AUTOSAR XML (schema 4-2-2)
package /STELLANTIS/EPT/COMSWCs
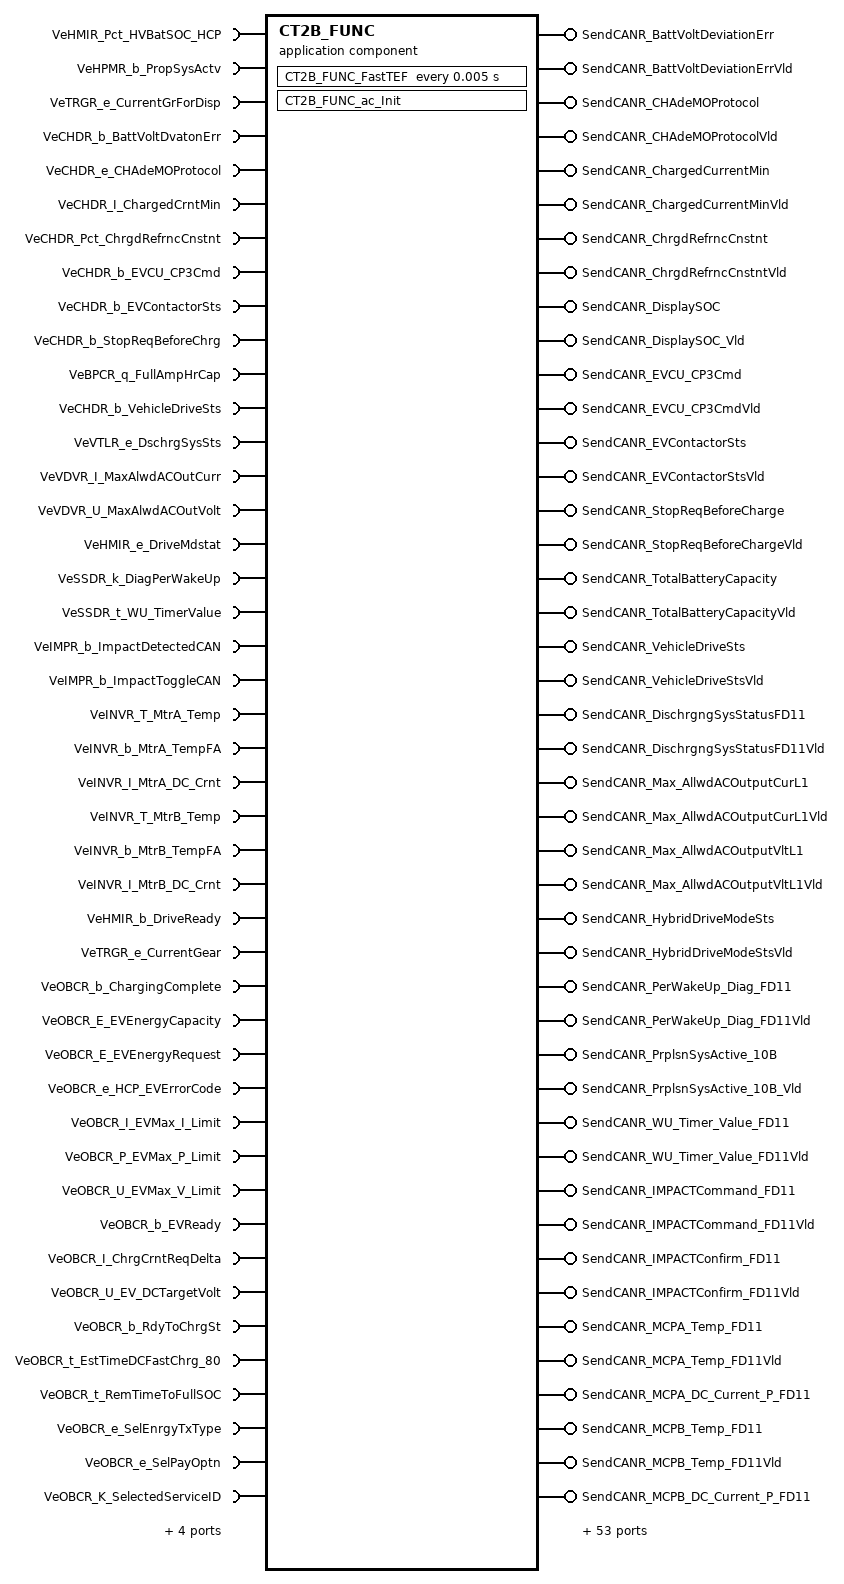
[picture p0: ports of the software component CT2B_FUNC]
  application sw component type CT2B_FUNC
    48 x require port:
      VeHMIR_Pct_HVBatSOC_HCP: nonqueued-receiver-com-spec{data-element=Value, init-value=0}, required-interface=VeHMIR_Pct_HVBatSOC_HCP
      VeHPMR_b_PropSysActv: nonqueued-receiver-com-spec{data-element=Value, init-value=0}, required-interface=VeHPMR_b_PropSysActv
      VeTRGR_e_CurrentGrForDisp: nonqueued-receiver-com-spec{data-element=Value, init-value=0}, required-interface=VeTRGR_e_CurrentGrForDisp
      VeCHDR_b_BattVoltDvatonErr: variation-point={short-label=vpVeCHDR_b_BattVoltDvatonErr, sw-syscond=1}, nonqueued-receiver-com-spec{data-element=Value, init-value=0}, required-interface=VeCHDR_b_BattVoltDvatonErr
      VeCHDR_e_CHAdeMOProtocol: variation-point={short-label=vpVeCHDR_e_CHAdeMOProtocol, sw-syscond=1}, nonqueued-receiver-com-spec{data-element=Value, init-value=CeIDCR_e_CHAdeMO_0_9_n_earlier}, required-interface=VeCHDR_e_CHAdeMOProtocol
      VeCHDR_I_ChargedCrntMin: variation-point={short-label=vpVeCHDR_I_ChargedCrntMin, sw-syscond=1}, nonqueued-receiver-com-spec{data-element=Value, init-value=0}, required-interface=VeCHDR_I_ChargedCrntMin
      VeCHDR_Pct_ChrgdRefrncCnstnt: variation-point={short-label=vpVeCHDR_Pct_ChrgdRefrncCnstnt, sw-syscond=1}, nonqueued-receiver-com-spec{data-element=Value, init-value=0}, required-interface=VeCHDR_Pct_ChrgdRefrncCnstnt
      VeCHDR_b_EVCU_CP3Cmd: variation-point={short-label=vpVeCHDR_b_EVCU_CP3Cmd, sw-syscond=1}, nonqueued-receiver-com-spec{data-element=Value, init-value=0}, required-interface=VeCHDR_b_EVCU_CP3Cmd
      VeCHDR_b_EVContactorSts: variation-point={short-label=vpVeCHDR_b_EVContactorSts, sw-syscond=1}, nonqueued-receiver-com-spec{data-element=Value, init-value=0}, required-interface=VeCHDR_b_EVContactorSts
      VeCHDR_b_StopReqBeforeChrg: variation-point={short-label=vpVeCHDR_b_StopReqBeforeChrg, sw-syscond=1}, nonqueued-receiver-com-spec{data-element=Value, init-value=0}, required-interface=VeCHDR_b_StopReqBeforeChrg
      VeBPCR_q_FullAmpHrCap: variation-point={short-label=vpVeBPCR_q_FullAmpHrCap, sw-syscond=1}, nonqueued-receiver-com-spec{data-element=Value, init-value=0}, required-interface=VeBPCR_q_FullAmpHrCap
      VeCHDR_b_VehicleDriveSts: variation-point={short-label=vpVeCHDR_b_VehicleDriveSts, sw-syscond=1}, nonqueued-receiver-com-spec{data-element=Value, init-value=0}, required-interface=VeCHDR_b_VehicleDriveSts
      VeVTLR_e_DschrgSysSts: nonqueued-receiver-com-spec{data-element=Value, init-value=CeVTLR_e_DschrgInactv}, required-interface=VeVTLR_e_DschrgSysSts
      VeVDVR_I_MaxAlwdACOutCurr: variation-point={short-label=vpVeVDVR_I_MaxAlwdACOutCurr, sw-syscond=1}, nonqueued-receiver-com-spec{data-element=Value, init-value=0}, required-interface=VeVDVR_I_MaxAlwdACOutCurr
      VeVDVR_U_MaxAlwdACOutVolt: variation-point={short-label=vpVeVDVR_U_MaxAlwdACOutVolt, sw-syscond=1}, nonqueued-receiver-com-spec{data-element=Value, init-value=0}, required-interface=VeVDVR_U_MaxAlwdACOutVolt
      VeHMIR_e_DriveMdstat: nonqueued-receiver-com-spec{data-element=Value, init-value=0}, required-interface=VeHMIR_e_DriveMdstat
      VeSSDR_k_DiagPerWakeUp: nonqueued-receiver-com-spec{data-element=Value, init-value=0}, required-interface=VeSSDR_k_DiagPerWakeUp
      VeSSDR_t_WU_TimerValue: nonqueued-receiver-com-spec{data-element=Value, init-value=0}, required-interface=VeSSDR_t_WU_TimerValue
      VeIMPR_b_ImpactDetectedCAN: nonqueued-receiver-com-spec{data-element=Value, init-value=0}, required-interface=VeIMPR_b_ImpactDetectedCAN
      VeIMPR_b_ImpactToggleCAN: nonqueued-receiver-com-spec{data-element=Value, init-value=0}, required-interface=VeIMPR_b_ImpactToggleCAN
      VeINVR_T_MtrA_Temp: variation-point={short-label=vpVeINVR_T_MtrA_Temp, sw-syscond=1}, nonqueued-receiver-com-spec{data-element=Value, init-value=0}, required-interface=VeINVR_T_MtrA_Temp
      VeINVR_b_MtrA_TempFA: variation-point={short-label=vpVeINVR_b_MtrA_TempFA, sw-syscond=1}, nonqueued-receiver-com-spec{data-element=Value, init-value=0}, required-interface=VeINVR_b_MtrA_TempFA
      VeINVR_I_MtrA_DC_Crnt: variation-point={short-label=vpVeINVR_I_MtrA_DC_Crnt, sw-syscond=1}, nonqueued-receiver-com-spec{data-element=Value, init-value=0}, required-interface=VeINVR_I_MtrA_DC_Crnt
      VeINVR_T_MtrB_Temp: nonqueued-receiver-com-spec{data-element=Value, init-value=0}, required-interface=VeINVR_T_MtrB_Temp
      VeINVR_b_MtrB_TempFA: nonqueued-receiver-com-spec{data-element=Value, init-value=0}, required-interface=VeINVR_b_MtrB_TempFA
      VeINVR_I_MtrB_DC_Crnt: nonqueued-receiver-com-spec{data-element=Value, init-value=0}, required-interface=VeINVR_I_MtrB_DC_Crnt
      VeHMIR_b_DriveReady: nonqueued-receiver-com-spec{data-element=Value, init-value=0}, required-interface=VeHMIR_b_DriveReady
      VeTRGR_e_CurrentGear: nonqueued-receiver-com-spec{data-element=Value, init-value=0}, required-interface=VeTRGR_e_CurrentGear
      VeOBCR_b_ChargingComplete: nonqueued-receiver-com-spec{data-element=Value, init-value=0}, required-interface=VeOBCR_b_ChargingComplete
      VeOBCR_E_EVEnergyCapacity: nonqueued-receiver-com-spec{data-element=Value, init-value=0}, required-interface=VeOBCR_E_EVEnergyCapacity
      VeOBCR_E_EVEnergyRequest: nonqueued-receiver-com-spec{data-element=Value, init-value=0}, required-interface=VeOBCR_E_EVEnergyRequest
      VeOBCR_e_HCP_EVErrorCode: nonqueued-receiver-com-spec{data-element=Value, init-value=0}, required-interface=VeOBCR_e_HCP_EVErrorCode
      VeOBCR_I_EVMax_I_Limit: nonqueued-receiver-com-spec{data-element=Value, init-value=0}, required-interface=VeOBCR_I_EVMax_I_Limit
      VeOBCR_P_EVMax_P_Limit: nonqueued-receiver-com-spec{data-element=Value, init-value=0}, required-interface=VeOBCR_P_EVMax_P_Limit
      VeOBCR_U_EVMax_V_Limit: nonqueued-receiver-com-spec{data-element=Value, init-value=0}, required-interface=VeOBCR_U_EVMax_V_Limit
      VeOBCR_b_EVReady: nonqueued-receiver-com-spec{data-element=Value, init-value=0}, required-interface=VeOBCR_b_EVReady
      VeOBCR_I_ChrgCrntReqDelta: nonqueued-receiver-com-spec{data-element=Value, init-value=0}, required-interface=VeOBCR_I_ChrgCrntReqDelta
      VeOBCR_U_EV_DCTargetVolt: nonqueued-receiver-com-spec{data-element=Value, init-value=0}, required-interface=VeOBCR_U_EV_DCTargetVolt
      VeOBCR_b_RdyToChrgSt: nonqueued-receiver-com-spec{data-element=Value, init-value=0}, required-interface=VeOBCR_b_RdyToChrgSt
      VeOBCR_t_EstTimeDCFastChrg_80: nonqueued-receiver-com-spec{data-element=Value, init-value=0}, required-interface=VeOBCR_t_EstTimeDCFastChrg_80
      VeOBCR_t_RemTimeToFullSOC: nonqueued-receiver-com-spec{data-element=Value, init-value=0}, required-interface=VeOBCR_t_RemTimeToFullSOC
      VeOBCR_e_SelEnrgyTxType: nonqueued-receiver-com-spec{data-element=Value, init-value=0}, required-interface=VeOBCR_e_SelEnrgyTxType
      VeOBCR_e_SelPayOptn: nonqueued-receiver-com-spec{data-element=Value, init-value=CeOBCR_e_NoPaymentSel}, required-interface=VeOBCR_e_SelPayOptn
      VeOBCR_K_SelectedServiceID: nonqueued-receiver-com-spec{data-element=Value, init-value=0}, required-interface=VeOBCR_K_SelectedServiceID
      VeOBCR_e_Service_Category: nonqueued-receiver-com-spec{data-element=Value, init-value=0}, required-interface=VeOBCR_e_Service_Category
      VeOBCR_d_ServiceScope: variation-point={short-label=vpVeOBCR_d_ServiceScope, sw-syscond=1}, nonqueued-receiver-com-spec{data-element=Value, init-value=0}, required-interface=VeOBCR_d_ServiceScope
      VeVTHR_b_V2H_SelEnergyTransType: variation-point={short-label=vpVeVTHR_b_V2H_SelEnergyTransType, sw-syscond=1}, nonqueued-receiver-com-spec{data-element=Value, init-value=0}, required-interface=VeVTHR_b_V2H_SelEnergyTransType
      VeVTHR_Pct_V2H_BattBulkSOC: variation-point={short-label=vpVeVTHR_Pct_V2H_BattBulkSOC, sw-syscond=1}, nonqueued-receiver-com-spec{data-element=Value, init-value=0}, required-interface=VeVTHR_Pct_V2H_BattBulkSOC
    97 x provide port:
      SendCANR_BattVoltDeviationErr: variation-point={short-label=vpSendCANR_BattVoltDeviationErr, sw-syscond=1}, nonqueued-sender-com-spec{data-element=SendCANR_BattVoltDeviationErr, init-value=0}, provided-interface=SendCANR_BattVoltDeviationErr
      SendCANR_BattVoltDeviationErrVld: variation-point={short-label=vpSendCANR_BattVoltDeviationErrVld, sw-syscond=1}, nonqueued-sender-com-spec{data-element=SendCANR_BattVoltDeviationErrVld, init-value=0}, provided-interface=SendCANR_BattVoltDeviationErrVld
      SendCANR_CHAdeMOProtocol: variation-point={short-label=vpSendCANR_CHAdeMOProtocol, sw-syscond=1}, nonqueued-sender-com-spec{data-element=SendCANR_CHAdeMOProtocol, init-value=0}, provided-interface=SendCANR_CHAdeMOProtocol
      SendCANR_CHAdeMOProtocolVld: variation-point={short-label=vpSendCANR_CHAdeMOProtocolVld, sw-syscond=1}, nonqueued-sender-com-spec{data-element=SendCANR_CHAdeMOProtocolVld, init-value=0}, provided-interface=SendCANR_CHAdeMOProtocolVld
      SendCANR_ChargedCurrentMin: variation-point={short-label=vpSendCANR_ChargedCurrentMin, sw-syscond=1}, nonqueued-sender-com-spec{data-element=SendCANR_ChargedCurrentMin, init-value=0}, provided-interface=SendCANR_ChargedCurrentMin
      SendCANR_ChargedCurrentMinVld: variation-point={short-label=vpSendCANR_ChargedCurrentMinVld, sw-syscond=1}, nonqueued-sender-com-spec{data-element=SendCANR_ChargedCurrentMinVld, init-value=0}, provided-interface=SendCANR_ChargedCurrentMinVld
      SendCANR_ChrgdRefrncCnstnt: variation-point={short-label=vpSendCANR_ChrgdRefrncCnstnt, sw-syscond=1}, nonqueued-sender-com-spec{data-element=SendCANR_ChrgdRefrncCnstnt, init-value=0}, provided-interface=SendCANR_ChrgdRefrncCnstnt
      SendCANR_ChrgdRefrncCnstntVld: variation-point={short-label=vpSendCANR_ChrgdRefrncCnstntVld, sw-syscond=1}, nonqueued-sender-com-spec{data-element=SendCANR_ChrgdRefrncCnstntVld, init-value=0}, provided-interface=SendCANR_ChrgdRefrncCnstntVld
      SendCANR_DisplaySOC: variation-point={short-label=vpSendCANR_DisplaySOC, sw-syscond=1}, nonqueued-sender-com-spec{data-element=SendCANR_DisplaySOC, init-value=0}, provided-interface=SendCANR_DisplaySOC
      SendCANR_DisplaySOC_Vld: variation-point={short-label=vpSendCANR_DisplaySOC_Vld, sw-syscond=1}, nonqueued-sender-com-spec{data-element=SendCANR_DisplaySOC_Vld, init-value=0}, provided-interface=SendCANR_DisplaySOC_Vld
      SendCANR_EVCU_CP3Cmd: variation-point={short-label=vpSendCANR_EVCU_CP3Cmd, sw-syscond=1}, nonqueued-sender-com-spec{data-element=SendCANR_EVCU_CP3Cmd, init-value=0}, provided-interface=SendCANR_EVCU_CP3Cmd
      SendCANR_EVCU_CP3CmdVld: variation-point={short-label=vpSendCANR_EVCU_CP3CmdVld, sw-syscond=1}, nonqueued-sender-com-spec{data-element=SendCANR_EVCU_CP3CmdVld, init-value=0}, provided-interface=SendCANR_EVCU_CP3CmdVld
      SendCANR_EVContactorSts: variation-point={short-label=vpSendCANR_EVContactorSts, sw-syscond=1}, nonqueued-sender-com-spec{data-element=SendCANR_EVContactorSts, init-value=0}, provided-interface=SendCANR_EVContactorSts
      SendCANR_EVContactorStsVld: variation-point={short-label=vpSendCANR_EVContactorStsVld, sw-syscond=1}, nonqueued-sender-com-spec{data-element=SendCANR_EVContactorStsVld, init-value=0}, provided-interface=SendCANR_EVContactorStsVld
      SendCANR_StopReqBeforeCharge: variation-point={short-label=vpSendCANR_StopReqBeforeCharge, sw-syscond=1}, nonqueued-sender-com-spec{data-element=SendCANR_StopReqBeforeCharge, init-value=0}, provided-interface=SendCANR_StopReqBeforeCharge
      SendCANR_StopReqBeforeChargeVld: variation-point={short-label=vpSendCANR_StopReqBeforeChargeVld, sw-syscond=1}, nonqueued-sender-com-spec{data-element=SendCANR_StopReqBeforeChargeVld, init-value=0}, provided-interface=SendCANR_StopReqBeforeChargeVld
      SendCANR_TotalBatteryCapacity: variation-point={short-label=vpSendCANR_TotalBatteryCapacity, sw-syscond=1}, nonqueued-sender-com-spec{data-element=SendCANR_TotalBatteryCapacity, init-value=0}, provided-interface=SendCANR_TotalBatteryCapacity
      SendCANR_TotalBatteryCapacityVld: variation-point={short-label=vpSendCANR_TotalBatteryCapacityVld, sw-syscond=1}, nonqueued-sender-com-spec{data-element=SendCANR_TotalBatteryCapacityVld, init-value=0}, provided-interface=SendCANR_TotalBatteryCapacityVld
      SendCANR_VehicleDriveSts: variation-point={short-label=vpSendCANR_VehicleDriveSts, sw-syscond=1}, nonqueued-sender-com-spec{data-element=SendCANR_VehicleDriveSts, init-value=0}, provided-interface=SendCANR_VehicleDriveSts
      SendCANR_VehicleDriveStsVld: variation-point={short-label=vpSendCANR_VehicleDriveStsVld, sw-syscond=1}, nonqueued-sender-com-spec{data-element=SendCANR_VehicleDriveStsVld, init-value=0}, provided-interface=SendCANR_VehicleDriveStsVld
      SendCANR_DischrgngSysStatusFD11: nonqueued-sender-com-spec{data-element=SendCANR_DischrgngSysStatusFD11, init-value=0}, provided-interface=SendCANR_DischrgngSysStatusFD11
      SendCANR_DischrgngSysStatusFD11Vld: nonqueued-sender-com-spec{data-element=SendCANR_DischrgngSysStatusFD11Vld, init-value=0}, provided-interface=SendCANR_DischrgngSysStatusFD11Vld
      SendCANR_Max_AllwdACOutputCurL1: variation-point={short-label=vpSendCANR_Max_AllwdACOutputCurL1, sw-syscond=1}, nonqueued-sender-com-spec{data-element=SendCANR_Max_AllwdACOutputCurL1, init-value=0}, provided-interface=SendCANR_Max_AllwdACOutputCurL1
      SendCANR_Max_AllwdACOutputCurL1Vld: variation-point={short-label=vpSendCANR_Max_AllwdACOutputCurL1Vld, sw-syscond=1}, nonqueued-sender-com-spec{data-element=SendCANR_Max_AllwdACOutputCurL1Vld, init-value=0}, provided-interface=SendCANR_Max_AllwdACOutputCurL1Vld
      SendCANR_Max_AllwdACOutputVltL1: variation-point={short-label=vpSendCANR_Max_AllwdACOutputVltL1, sw-syscond=1}, nonqueued-sender-com-spec{data-element=SendCANR_Max_AllwdACOutputVltL1, init-value=0}, provided-interface=SendCANR_Max_AllwdACOutputVltL1
      SendCANR_Max_AllwdACOutputVltL1Vld: variation-point={short-label=vpSendCANR_Max_AllwdACOutputVltL1Vld, sw-syscond=1}, nonqueued-sender-com-spec{data-element=SendCANR_Max_AllwdACOutputVltL1Vld, init-value=0}, provided-interface=SendCANR_Max_AllwdACOutputVltL1Vld
      SendCANR_HybridDriveModeSts: nonqueued-sender-com-spec{data-element=SendCANR_HybridDriveModeSts, init-value=0}, provided-interface=SendCANR_HybridDriveModeSts
      SendCANR_HybridDriveModeStsVld: nonqueued-sender-com-spec{data-element=SendCANR_HybridDriveModeStsVld, init-value=0}, provided-interface=SendCANR_HybridDriveModeStsVld
      SendCANR_PerWakeUp_Diag_FD11: nonqueued-sender-com-spec{data-element=SendCANR_PerWakeUp_Diag_FD11, init-value=0}, provided-interface=SendCANR_PerWakeUp_Diag_FD11
      SendCANR_PerWakeUp_Diag_FD11Vld: nonqueued-sender-com-spec{data-element=SendCANR_PerWakeUp_Diag_FD11Vld, init-value=0}, provided-interface=SendCANR_PerWakeUp_Diag_FD11Vld
      SendCANR_PrplsnSysActive_10B: nonqueued-sender-com-spec{data-element=SendCANR_PrplsnSysActive_10B, init-value=0}, provided-interface=SendCANR_PrplsnSysActive_10B
      SendCANR_PrplsnSysActive_10B_Vld: nonqueued-sender-com-spec{data-element=SendCANR_PrplsnSysActive_10B_Vld, init-value=0}, provided-interface=SendCANR_PrplsnSysActive_10B_Vld
      SendCANR_WU_Timer_Value_FD11: nonqueued-sender-com-spec{data-element=SendCANR_WU_Timer_Value_FD11, init-value=0}, provided-interface=SendCANR_WU_Timer_Value_FD11
      SendCANR_WU_Timer_Value_FD11Vld: nonqueued-sender-com-spec{data-element=SendCANR_WU_Timer_Value_FD11Vld, init-value=0}, provided-interface=SendCANR_WU_Timer_Value_FD11Vld
      SendCANR_IMPACTCommand_FD11: nonqueued-sender-com-spec{data-element=SendCANR_IMPACTCommand_FD11, init-value=0}, provided-interface=SendCANR_IMPACTCommand_FD11
      SendCANR_IMPACTCommand_FD11Vld: nonqueued-sender-com-spec{data-element=SendCANR_IMPACTCommand_FD11Vld, init-value=0}, provided-interface=SendCANR_IMPACTCommand_FD11Vld
      SendCANR_IMPACTConfirm_FD11: nonqueued-sender-com-spec{data-element=SendCANR_IMPACTConfirm_FD11, init-value=0}, provided-interface=SendCANR_IMPACTConfirm_FD11
      SendCANR_IMPACTConfirm_FD11Vld: nonqueued-sender-com-spec{data-element=SendCANR_IMPACTConfirm_FD11Vld, init-value=0}, provided-interface=SendCANR_IMPACTConfirm_FD11Vld
      SendCANR_MCPA_Temp_FD11: variation-point={short-label=vpSendCANR_MCPA_Temp_FD11, sw-syscond=1}, nonqueued-sender-com-spec{data-element=SendCANR_MCPA_Temp_FD11, init-value=0}, provided-interface=SendCANR_MCPA_Temp_FD11
      SendCANR_MCPA_Temp_FD11Vld: variation-point={short-label=vpSendCANR_MCPA_Temp_FD11Vld, sw-syscond=1}, nonqueued-sender-com-spec{data-element=SendCANR_MCPA_Temp_FD11Vld, init-value=0}, provided-interface=SendCANR_MCPA_Temp_FD11Vld
      SendCANR_MCPA_DC_Current_P_FD11: variation-point={short-label=vpSendCANR_MCPA_DC_Current_P_FD11, sw-syscond=1}, nonqueued-sender-com-spec{data-element=SendCANR_MCPA_DC_Current_P_FD11, init-value=0}, provided-interface=SendCANR_MCPA_DC_Current_P_FD11
      SendCANR_MCPB_Temp_FD11: nonqueued-sender-com-spec{data-element=SendCANR_MCPB_Temp_FD11, init-value=0}, provided-interface=SendCANR_MCPB_Temp_FD11
      SendCANR_MCPB_Temp_FD11Vld: nonqueued-sender-com-spec{data-element=SendCANR_MCPB_Temp_FD11Vld, init-value=0}, provided-interface=SendCANR_MCPB_Temp_FD11Vld
      SendCANR_MCPB_DC_Current_P_FD11: nonqueued-sender-com-spec{data-element=SendCANR_MCPB_DC_Current_P_FD11, init-value=0}, provided-interface=SendCANR_MCPB_DC_Current_P_FD11
      SendCANR_MCPB_DC_Current_P_FD11Vld: nonqueued-sender-com-spec{data-element=SendCANR_MCPB_DC_Current_P_FD11Vld, init-value=0}, provided-interface=SendCANR_MCPB_DC_Current_P_FD11Vld
      SendCANR_DriveReady_PT_FD11: nonqueued-sender-com-spec{data-element=SendCANR_DriveReady_PT_FD11, init-value=0}, provided-interface=SendCANR_DriveReady_PT_FD11
      SendCANR_DriveReady_PT_FD11Vld: nonqueued-sender-com-spec{data-element=SendCANR_DriveReady_PT_FD11Vld, init-value=0}, provided-interface=SendCANR_DriveReady_PT_FD11Vld
      SendCANR_GearEngdForDispPTFD11: nonqueued-sender-com-spec{data-element=SendCANR_GearEngdForDispPTFD11, init-value=0}, provided-interface=SendCANR_GearEngdForDispPTFD11
      SendCANR_GearEngdForDispPTFD11Vld: nonqueued-sender-com-spec{data-element=SendCANR_GearEngdForDispPTFD11Vld, init-value=0}, provided-interface=SendCANR_GearEngdForDispPTFD11Vld
      SendCANR_GearEngaged_PT_FD11: nonqueued-sender-com-spec{data-element=SendCANR_GearEngaged_PT_FD11, init-value=0}, provided-interface=SendCANR_GearEngaged_PT_FD11
      SendCANR_GearEngaged_PT_FD11Vld: nonqueued-sender-com-spec{data-element=SendCANR_GearEngaged_PT_FD11Vld, init-value=0}, provided-interface=SendCANR_GearEngaged_PT_FD11Vld
      SendCANR_PtrainPrplsnActvPTFD11: nonqueued-sender-com-spec{data-element=SendCANR_PtrainPrplsnActvPTFD11, init-value=0}, provided-interface=SendCANR_PtrainPrplsnActvPTFD11
      SendCANR_PtrainPrplsnActvPTFD11Vld: nonqueued-sender-com-spec{data-element=SendCANR_PtrainPrplsnActvPTFD11Vld, init-value=0}, provided-interface=SendCANR_PtrainPrplsnActvPTFD11Vld
      SendCANR_GearEngagedForDisplay: nonqueued-sender-com-spec{data-element=SendCANR_GearEngagedForDisplay, init-value=0}, provided-interface=SendCANR_GearEngagedForDisplay
      SendCANR_GearEngagedForDisplayVld: nonqueued-sender-com-spec{data-element=SendCANR_GearEngagedForDisplayVld, init-value=0}, provided-interface=SendCANR_GearEngagedForDisplayVld
      SendCANR_HVCMS_ChrgnCmpl_FD11: nonqueued-sender-com-spec{data-element=SendCANR_HVCMS_ChrgnCmpl_FD11, init-value=0}, provided-interface=SendCANR_HVCMS_ChrgnCmpl_FD11
      SendCANR_HVCMS_ChrgnCmpl_FD11Vld: nonqueued-sender-com-spec{data-element=SendCANR_HVCMS_ChrgnCmpl_FD11Vld, init-value=0}, provided-interface=SendCANR_HVCMS_ChrgnCmpl_FD11Vld
      SendCANR_HVCMS_EVEgyCap_FD11: nonqueued-sender-com-spec{data-element=SendCANR_HVCMS_EVEgyCap_FD11, init-value=0}, provided-interface=SendCANR_HVCMS_EVEgyCap_FD11
      SendCANR_HVCMS_EVEgyCap_FD11Vld: nonqueued-sender-com-spec{data-element=SendCANR_HVCMS_EVEgyCap_FD11Vld, init-value=0}, provided-interface=SendCANR_HVCMS_EVEgyCap_FD11Vld
      SendCANR_HVCMS_EVEgyReq_FD11: nonqueued-sender-com-spec{data-element=SendCANR_HVCMS_EVEgyReq_FD11, init-value=0}, provided-interface=SendCANR_HVCMS_EVEgyReq_FD11
      SendCANR_HVCMS_EVEgyReq_FD11Vld: nonqueued-sender-com-spec{data-element=SendCANR_HVCMS_EVEgyReq_FD11Vld, init-value=0}, provided-interface=SendCANR_HVCMS_EVEgyReq_FD11Vld
      SendCANR_HVCMS_EVErrorCode_FD11: nonqueued-sender-com-spec{data-element=SendCANR_HVCMS_EVErrorCode_FD11, init-value=0}, provided-interface=SendCANR_HVCMS_EVErrorCode_FD11
      SendCANR_HVCMS_EVErrorCode_FD11Vld: nonqueued-sender-com-spec{data-element=SendCANR_HVCMS_EVErrorCode_FD11Vld, init-value=0}, provided-interface=SendCANR_HVCMS_EVErrorCode_FD11Vld
      SendCANR_HVCMS_EVMaxILimit_FD11: nonqueued-sender-com-spec{data-element=SendCANR_HVCMS_EVMaxILimit_FD11, init-value=0}, provided-interface=SendCANR_HVCMS_EVMaxILimit_FD11
      SendCANR_HVCMS_EVMaxILimit_FD11Vld: nonqueued-sender-com-spec{data-element=SendCANR_HVCMS_EVMaxILimit_FD11Vld, init-value=0}, provided-interface=SendCANR_HVCMS_EVMaxILimit_FD11Vld
      SendCANR_HVCMS_EVMaxPLimit_FD11: nonqueued-sender-com-spec{data-element=SendCANR_HVCMS_EVMaxPLimit_FD11, init-value=0}, provided-interface=SendCANR_HVCMS_EVMaxPLimit_FD11
      SendCANR_HVCMS_EVMaxPLimit_FD11Vld: nonqueued-sender-com-spec{data-element=SendCANR_HVCMS_EVMaxPLimit_FD11Vld, init-value=0}, provided-interface=SendCANR_HVCMS_EVMaxPLimit_FD11Vld
      SendCANR_HVCMSEVMaxVLimit_FD11: nonqueued-sender-com-spec{data-element=SendCANR_HVCMSEVMaxVLimit_FD11, init-value=0}, provided-interface=SendCANR_HVCMSEVMaxVLimit_FD11
      SendCANR_HVCMSEVMaxVLimit_FD11Vld: nonqueued-sender-com-spec{data-element=SendCANR_HVCMSEVMaxVLimit_FD11Vld, init-value=0}, provided-interface=SendCANR_HVCMSEVMaxVLimit_FD11Vld
      SendCANR_HVCMS_EVRESS_SOC_FD11: nonqueued-sender-com-spec{data-element=SendCANR_HVCMS_EVRESS_SOC_FD11, init-value=0}, provided-interface=SendCANR_HVCMS_EVRESS_SOC_FD11
      SendCANR_HVCMS_EVRESS_SOC_FD11Vld: nonqueued-sender-com-spec{data-element=SendCANR_HVCMS_EVRESS_SOC_FD11Vld, init-value=0}, provided-interface=SendCANR_HVCMS_EVRESS_SOC_FD11Vld
      SendCANR_HVCMS_EVReady_FD11: nonqueued-sender-com-spec{data-element=SendCANR_HVCMS_EVReady_FD11, init-value=0}, provided-interface=SendCANR_HVCMS_EVReady_FD11
      SendCANR_HVCMS_EVReady_FD11Vld: nonqueued-sender-com-spec{data-element=SendCANR_HVCMS_EVReady_FD11Vld, init-value=0}, provided-interface=SendCANR_HVCMS_EVReady_FD11Vld
      SendCANR_HVCMS_EVTarCurr_FD11: nonqueued-sender-com-spec{data-element=SendCANR_HVCMS_EVTarCurr_FD11, init-value=0}, provided-interface=SendCANR_HVCMS_EVTarCurr_FD11
      SendCANR_HVCMS_EVTarCurr_FD11Vld: nonqueued-sender-com-spec{data-element=SendCANR_HVCMS_EVTarCurr_FD11Vld, init-value=0}, provided-interface=SendCANR_HVCMS_EVTarCurr_FD11Vld
      SendCANR_HVCMS_EVTarVolt_FD11: nonqueued-sender-com-spec{data-element=SendCANR_HVCMS_EVTarVolt_FD11, init-value=0}, provided-interface=SendCANR_HVCMS_EVTarVolt_FD11
      SendCANR_HVCMS_EVTarVolt_FD11Vld: nonqueued-sender-com-spec{data-element=SendCANR_HVCMS_EVTarVolt_FD11Vld, init-value=0}, provided-interface=SendCANR_HVCMS_EVTarVolt_FD11Vld
      SendCANR_HVCMS_RdyToChrgSt_FD11: nonqueued-sender-com-spec{data-element=SendCANR_HVCMS_RdyToChrgSt_FD11, init-value=0}, provided-interface=SendCANR_HVCMS_RdyToChrgSt_FD11
      SendCANR_HVCMS_RdyToChrgSt_FD11Vld: nonqueued-sender-com-spec{data-element=SendCANR_HVCMS_RdyToChrgSt_FD11Vld, init-value=0}, provided-interface=SendCANR_HVCMS_RdyToChrgSt_FD11Vld
      SendCANR_HVCMS_RmnTiToBuSOCFD11: nonqueued-sender-com-spec{data-element=SendCANR_HVCMS_RmnTiToBuSOCFD11, init-value=0}, provided-interface=SendCANR_HVCMS_RmnTiToBuSOCFD11
      SendCANR_HVCMS_RmnTiToBuSOCFD11Vld: nonqueued-sender-com-spec{data-element=SendCANR_HVCMS_RmnTiToBuSOCFD11Vld, init-value=0}, provided-interface=SendCANR_HVCMS_RmnTiToBuSOCFD11Vld
      SendCANR_HVCMS_RmnTiToFuSOCFD11: nonqueued-sender-com-spec{data-element=SendCANR_HVCMS_RmnTiToFuSOCFD11, init-value=0}, provided-interface=SendCANR_HVCMS_RmnTiToFuSOCFD11
      SendCANR_HVCMS_RmnTiToFuSOCFD11Vld: nonqueued-sender-com-spec{data-element=SendCANR_HVCMS_RmnTiToFuSOCFD11Vld, init-value=0}, provided-interface=SendCANR_HVCMS_RmnTiToFuSOCFD11Vld
      SendCANR_HVCMS_SelEgyTrfTypFD11: nonqueued-sender-com-spec{data-element=SendCANR_HVCMS_SelEgyTrfTypFD11, init-value=0}, provided-interface=SendCANR_HVCMS_SelEgyTrfTypFD11
      SendCANR_HVCMS_SelEgyTrfTypFD11Vld: nonqueued-sender-com-spec{data-element=SendCANR_HVCMS_SelEgyTrfTypFD11Vld, init-value=0}, provided-interface=SendCANR_HVCMS_SelEgyTrfTypFD11Vld
      SendCANR_HVCMS_SelPmtOptn_FD11: nonqueued-sender-com-spec{data-element=SendCANR_HVCMS_SelPmtOptn_FD11, init-value=0}, provided-interface=SendCANR_HVCMS_SelPmtOptn_FD11
      SendCANR_HVCMS_SelPmtOptn_FD11Vld: nonqueued-sender-com-spec{data-element=SendCANR_HVCMS_SelPmtOptn_FD11Vld, init-value=0}, provided-interface=SendCANR_HVCMS_SelPmtOptn_FD11Vld
      SendCANR_HVCMS_SelServId_FD11: nonqueued-sender-com-spec{data-element=SendCANR_HVCMS_SelServId_FD11, init-value=0}, provided-interface=SendCANR_HVCMS_SelServId_FD11
      SendCANR_HVCMS_SelServId_FD11Vld: nonqueued-sender-com-spec{data-element=SendCANR_HVCMS_SelServId_FD11Vld, init-value=0}, provided-interface=SendCANR_HVCMS_SelServId_FD11Vld
      SendCANR_HVCMS_ServCtgy_FD11: nonqueued-sender-com-spec{data-element=SendCANR_HVCMS_ServCtgy_FD11, init-value=0}, provided-interface=SendCANR_HVCMS_ServCtgy_FD11
      SendCANR_HVCMS_ServCtgy_FD11Vld: nonqueued-sender-com-spec{data-element=SendCANR_HVCMS_ServCtgy_FD11Vld, init-value=0}, provided-interface=SendCANR_HVCMS_ServCtgy_FD11Vld
      SendCANR_HVCMS_ServScope_FD11: variation-point={short-label=vpSendCANR_HVCMS_ServScope_FD11, sw-syscond=1}, nonqueued-sender-com-spec{data-element=SendCANR_HVCMS_ServScope_FD11, init-value=0}, provided-interface=SendCANR_HVCMS_ServScope_FD11
      SendCANR_HVCMS_ServScope_FD11Vld: variation-point={short-label=vpSendCANR_HVCMS_ServScope_FD11Vld, sw-syscond=1}, nonqueued-sender-com-spec{data-element=SendCANR_HVCMS_ServScope_FD11Vld, init-value=0}, provided-interface=SendCANR_HVCMS_ServScope_FD11Vld
      SendCANR_V2X_HVCMSSltdEngTrfTyp: variation-point={short-label=vpSendCANR_V2X_HVCMSSltdEngTrfTyp, sw-syscond=1}, nonqueued-sender-com-spec{data-element=SendCANR_V2X_HVCMSSltdEngTrfTyp, init-value=0}, provided-interface=SendCANR_V2X_HVCMSSltdEngTrfTyp
      SendCANR_V2X_HVCMSSltdEngTrfTypVld: variation-point={short-label=vpSendCANR_V2X_HVCMSSltdEngTrfTypVld, sw-syscond=1}, nonqueued-sender-com-spec{data-element=SendCANR_V2X_HVCMSSltdEngTrfTypVld, init-value=0}, provided-interface=SendCANR_V2X_HVCMSSltdEngTrfTypVld
      SendCANR_VDCM_BattBulkSOC_FD11: variation-point={short-label=vpSendCANR_VDCM_BattBulkSOC_FD11, sw-syscond=1}, nonqueued-sender-com-spec{data-element=SendCANR_VDCM_BattBulkSOC_FD11, init-value=0}, provided-interface=SendCANR_VDCM_BattBulkSOC_FD11
      SendCANR_VDCM_BattBulkSOC_FD11Vld: variation-point={short-label=vpSendCANR_VDCM_BattBulkSOC_FD11Vld, sw-syscond=1}, nonqueued-sender-com-spec{data-element=SendCANR_VDCM_BattBulkSOC_FD11Vld, init-value=0}, provided-interface=SendCANR_VDCM_BattBulkSOC_FD11Vld
    behavior IB_CT2B_FUNC: data-type-mapping=[msADTtoIDTMapping, ADTtoIDTMapping], handle-termination-and-restart=NO-SUPPORT
      timing event Event_FastTEF: start-on-event=CT2B_FUNC_FastTEF, period=0.005
      init event Event_CT2B_FUNC_ac_Init: start-on-event=CT2B_FUNC_ac_Init
      runnable CT2B_FUNC_ac_Init
      runnable CT2B_FUNC_FastTEF
        data-receive-point-by-arguments:
          48 x access:
            IN_VeBPCR_q_FullAmpHrCap_Value: accessed-variable=VeBPCR_q_FullAmpHrCap.Value, variation-point={short-label=vpIN_VeBPCR_q_FullAmpHrCap_Value, sw-syscond=1}
            IN_VeCHDR_I_ChargedCrntMin_Value: accessed-variable=VeCHDR_I_ChargedCrntMin.Value, variation-point={short-label=vpIN_VeCHDR_I_ChargedCrntMin_Value, sw-syscond=1}
            IN_VeCHDR_Pct_ChrgdRefrncCnstnt_Value: accessed-variable=VeCHDR_Pct_ChrgdRefrncCnstnt.Value, variation-point={short-label=vpIN_VeCHDR_Pct_ChrgdRefrncCnstnt_Value, sw-syscond=1}
            IN_VeCHDR_b_BattVoltDvatonErr_Value: accessed-variable=VeCHDR_b_BattVoltDvatonErr.Value, variation-point={short-label=vpIN_VeCHDR_b_BattVoltDvatonErr_Value, sw-syscond=1}
            IN_VeCHDR_b_EVCU_CP3Cmd_Value: accessed-variable=VeCHDR_b_EVCU_CP3Cmd.Value, variation-point={short-label=vpIN_VeCHDR_b_EVCU_CP3Cmd_Value, sw-syscond=1}
            IN_VeCHDR_b_EVContactorSts_Value: accessed-variable=VeCHDR_b_EVContactorSts.Value, variation-point={short-label=vpIN_VeCHDR_b_EVContactorSts_Value, sw-syscond=1}
            IN_VeCHDR_b_StopReqBeforeChrg_Value: accessed-variable=VeCHDR_b_StopReqBeforeChrg.Value, variation-point={short-label=vpIN_VeCHDR_b_StopReqBeforeChrg_Value, sw-syscond=1}
            IN_VeCHDR_b_VehicleDriveSts_Value: accessed-variable=VeCHDR_b_VehicleDriveSts.Value, variation-point={short-label=vpIN_VeCHDR_b_VehicleDriveSts_Value, sw-syscond=1}
            IN_VeCHDR_e_CHAdeMOProtocol_Value: accessed-variable=VeCHDR_e_CHAdeMOProtocol.Value, variation-point={short-label=vpIN_VeCHDR_e_CHAdeMOProtocol_Value, sw-syscond=1}
            IN_VeHMIR_Pct_HVBatSOC_HCP_Value: accessed-variable=VeHMIR_Pct_HVBatSOC_HCP.Value
            IN_VeHMIR_b_DriveReady_Value: accessed-variable=VeHMIR_b_DriveReady.Value
            IN_VeHMIR_e_DriveMdstat_Value: accessed-variable=VeHMIR_e_DriveMdstat.Value
            IN_VeHPMR_b_PropSysActv_Value: accessed-variable=VeHPMR_b_PropSysActv.Value
            IN_VeIMPR_b_ImpactDetectedCAN_Value: accessed-variable=VeIMPR_b_ImpactDetectedCAN.Value
            IN_VeIMPR_b_ImpactToggleCAN_Value: accessed-variable=VeIMPR_b_ImpactToggleCAN.Value
            IN_VeINVR_I_MtrA_DC_Crnt_Value: accessed-variable=VeINVR_I_MtrA_DC_Crnt.Value, variation-point={short-label=vpIN_VeINVR_I_MtrA_DC_Crnt_Value, sw-syscond=1}
            IN_VeINVR_I_MtrB_DC_Crnt_Value: accessed-variable=VeINVR_I_MtrB_DC_Crnt.Value
            IN_VeINVR_T_MtrA_Temp_Value: accessed-variable=VeINVR_T_MtrA_Temp.Value, variation-point={short-label=vpIN_VeINVR_T_MtrA_Temp_Value, sw-syscond=1}
            IN_VeINVR_T_MtrB_Temp_Value: accessed-variable=VeINVR_T_MtrB_Temp.Value
            IN_VeINVR_b_MtrA_TempFA_Value: accessed-variable=VeINVR_b_MtrA_TempFA.Value, variation-point={short-label=vpIN_VeINVR_b_MtrA_TempFA_Value, sw-syscond=1}
            IN_VeINVR_b_MtrB_TempFA_Value: accessed-variable=VeINVR_b_MtrB_TempFA.Value
            IN_VeOBCR_E_EVEnergyCapacity_Value: accessed-variable=VeOBCR_E_EVEnergyCapacity.Value
            IN_VeOBCR_E_EVEnergyRequest_Value: accessed-variable=VeOBCR_E_EVEnergyRequest.Value
            IN_VeOBCR_I_ChrgCrntReqDelta_Value: accessed-variable=VeOBCR_I_ChrgCrntReqDelta.Value
            IN_VeOBCR_I_EVMax_I_Limit_Value: accessed-variable=VeOBCR_I_EVMax_I_Limit.Value
            IN_VeOBCR_K_SelectedServiceID_Value: accessed-variable=VeOBCR_K_SelectedServiceID.Value
            IN_VeOBCR_P_EVMax_P_Limit_Value: accessed-variable=VeOBCR_P_EVMax_P_Limit.Value
            IN_VeOBCR_U_EVMax_V_Limit_Value: accessed-variable=VeOBCR_U_EVMax_V_Limit.Value
            IN_VeOBCR_U_EV_DCTargetVolt_Value: accessed-variable=VeOBCR_U_EV_DCTargetVolt.Value
            IN_VeOBCR_b_ChargingComplete_Value: accessed-variable=VeOBCR_b_ChargingComplete.Value
            IN_VeOBCR_b_EVReady_Value: accessed-variable=VeOBCR_b_EVReady.Value
            IN_VeOBCR_b_RdyToChrgSt_Value: accessed-variable=VeOBCR_b_RdyToChrgSt.Value
            IN_VeOBCR_d_ServiceScope_Value: accessed-variable=VeOBCR_d_ServiceScope.Value, variation-point={short-label=vpIN_VeOBCR_d_ServiceScope_Value, sw-syscond=1}
            IN_VeOBCR_e_HCP_EVErrorCode_Value: accessed-variable=VeOBCR_e_HCP_EVErrorCode.Value
            IN_VeOBCR_e_SelEnrgyTxType_Value: accessed-variable=VeOBCR_e_SelEnrgyTxType.Value
            IN_VeOBCR_e_SelPayOptn_Value: accessed-variable=VeOBCR_e_SelPayOptn.Value
            IN_VeOBCR_e_Service_Category_Value: accessed-variable=VeOBCR_e_Service_Category.Value
            IN_VeOBCR_t_EstTimeDCFastChrg_80_Value: accessed-variable=VeOBCR_t_EstTimeDCFastChrg_80.Value
            IN_VeOBCR_t_RemTimeToFullSOC_Value: accessed-variable=VeOBCR_t_RemTimeToFullSOC.Value
            IN_VeSSDR_k_DiagPerWakeUp_Value: accessed-variable=VeSSDR_k_DiagPerWakeUp.Value
            IN_VeSSDR_t_WU_TimerValue_Value: accessed-variable=VeSSDR_t_WU_TimerValue.Value
            IN_VeTRGR_e_CurrentGear_Value: accessed-variable=VeTRGR_e_CurrentGear.Value
            IN_VeTRGR_e_CurrentGrForDisp_Value: accessed-variable=VeTRGR_e_CurrentGrForDisp.Value
            IN_VeVDVR_I_MaxAlwdACOutCurr_Value: accessed-variable=VeVDVR_I_MaxAlwdACOutCurr.Value, variation-point={short-label=vpIN_VeVDVR_I_MaxAlwdACOutCurr_Value, sw-syscond=1}
            IN_VeVDVR_U_MaxAlwdACOutVolt_Value: accessed-variable=VeVDVR_U_MaxAlwdACOutVolt.Value, variation-point={short-label=vpIN_VeVDVR_U_MaxAlwdACOutVolt_Value, sw-syscond=1}
            IN_VeVTHR_Pct_V2H_BattBulkSOC_Value: accessed-variable=VeVTHR_Pct_V2H_BattBulkSOC.Value, variation-point={short-label=vpIN_VeVTHR_Pct_V2H_BattBulkSOC_Value, sw-syscond=1}
            IN_VeVTHR_b_V2H_SelEnergyTransType_Value: accessed-variable=VeVTHR_b_V2H_SelEnergyTransType.Value, variation-point={short-label=vpIN_VeVTHR_b_V2H_SelEnergyTransType_Value, sw-syscond=1}
            IN_VeVTLR_e_DschrgSysSts_Value: accessed-variable=VeVTLR_e_DschrgSysSts.Value
        data-send-points:
          97 x access:
            OUT_SendCANR_BattVoltDeviationErr_SendCANR_BattVoltDeviationErr: accessed-variable=SendCANR_BattVoltDeviationErr.SendCANR_BattVoltDeviationErr, variation-point={short-label=vpOUT_SendCANR_BattVoltDeviationErr_SendCANR_BattVoltDeviationErr, sw-syscond=1}
            OUT_SendCANR_BattVoltDeviationErrVld_SendCANR_BattVoltDeviationErrVld: accessed-variable=SendCANR_BattVoltDeviationErrVld.SendCANR_BattVoltDeviationErrVld, variation-point={short-label=vpOUT_SendCANR_BattVoltDeviationErrVld_SendCANR_BattVoltDeviationErrVld, sw-syscond=1}
            OUT_SendCANR_CHAdeMOProtocol_SendCANR_CHAdeMOProtocol: accessed-variable=SendCANR_CHAdeMOProtocol.SendCANR_CHAdeMOProtocol, variation-point={short-label=vpOUT_SendCANR_CHAdeMOProtocol_SendCANR_CHAdeMOProtocol, sw-syscond=1}
            OUT_SendCANR_CHAdeMOProtocolVld_SendCANR_CHAdeMOProtocolVld: accessed-variable=SendCANR_CHAdeMOProtocolVld.SendCANR_CHAdeMOProtocolVld, variation-point={short-label=vpOUT_SendCANR_CHAdeMOProtocolVld_SendCANR_CHAdeMOProtocolVld, sw-syscond=1}
            OUT_SendCANR_ChargedCurrentMin_SendCANR_ChargedCurrentMin: accessed-variable=SendCANR_ChargedCurrentMin.SendCANR_ChargedCurrentMin, variation-point={short-label=vpOUT_SendCANR_ChargedCurrentMin_SendCANR_ChargedCurrentMin, sw-syscond=1}
            OUT_SendCANR_ChargedCurrentMinVld_SendCANR_ChargedCurrentMinVld: accessed-variable=SendCANR_ChargedCurrentMinVld.SendCANR_ChargedCurrentMinVld, variation-point={short-label=vpOUT_SendCANR_ChargedCurrentMinVld_SendCANR_ChargedCurrentMinVld, sw-syscond=1}
            OUT_SendCANR_ChrgdRefrncCnstnt_SendCANR_ChrgdRefrncCnstnt: accessed-variable=SendCANR_ChrgdRefrncCnstnt.SendCANR_ChrgdRefrncCnstnt, variation-point={short-label=vpOUT_SendCANR_ChrgdRefrncCnstnt_SendCANR_ChrgdRefrncCnstnt, sw-syscond=1}
            OUT_SendCANR_ChrgdRefrncCnstntVld_SendCANR_ChrgdRefrncCnstntVld: accessed-variable=SendCANR_ChrgdRefrncCnstntVld.SendCANR_ChrgdRefrncCnstntVld, variation-point={short-label=vpOUT_SendCANR_ChrgdRefrncCnstntVld_SendCANR_ChrgdRefrncCnstntVld, sw-syscond=1}
            OUT_SendCANR_DisplaySOC_SendCANR_DisplaySOC: accessed-variable=SendCANR_DisplaySOC.SendCANR_DisplaySOC, variation-point={short-label=vpOUT_SendCANR_DisplaySOC_SendCANR_DisplaySOC, sw-syscond=1}
            OUT_SendCANR_DisplaySOC_Vld_SendCANR_DisplaySOC_Vld: accessed-variable=SendCANR_DisplaySOC_Vld.SendCANR_DisplaySOC_Vld, variation-point={short-label=vpOUT_SendCANR_DisplaySOC_Vld_SendCANR_DisplaySOC_Vld, sw-syscond=1}
            OUT_SendCANR_EVCU_CP3Cmd_SendCANR_EVCU_CP3Cmd: accessed-variable=SendCANR_EVCU_CP3Cmd.SendCANR_EVCU_CP3Cmd, variation-point={short-label=vpOUT_SendCANR_EVCU_CP3Cmd_SendCANR_EVCU_CP3Cmd, sw-syscond=1}
            OUT_SendCANR_EVCU_CP3CmdVld_SendCANR_EVCU_CP3CmdVld: accessed-variable=SendCANR_EVCU_CP3CmdVld.SendCANR_EVCU_CP3CmdVld, variation-point={short-label=vpOUT_SendCANR_EVCU_CP3CmdVld_SendCANR_EVCU_CP3CmdVld, sw-syscond=1}
            OUT_SendCANR_EVContactorSts_SendCANR_EVContactorSts: accessed-variable=SendCANR_EVContactorSts.SendCANR_EVContactorSts, variation-point={short-label=vpOUT_SendCANR_EVContactorSts_SendCANR_EVContactorSts, sw-syscond=1}
            OUT_SendCANR_EVContactorStsVld_SendCANR_EVContactorStsVld: accessed-variable=SendCANR_EVContactorStsVld.SendCANR_EVContactorStsVld, variation-point={short-label=vpOUT_SendCANR_EVContactorStsVld_SendCANR_EVContactorStsVld, sw-syscond=1}
            OUT_SendCANR_StopReqBeforeCharge_SendCANR_StopReqBeforeCharge: accessed-variable=SendCANR_StopReqBeforeCharge.SendCANR_StopReqBeforeCharge, variation-point={short-label=vpOUT_SendCANR_StopReqBeforeCharge_SendCANR_StopReqBeforeCharge, sw-syscond=1}
            OUT_SendCANR_StopReqBeforeChargeVld_SendCANR_StopReqBeforeChargeVld: accessed-variable=SendCANR_StopReqBeforeChargeVld.SendCANR_StopReqBeforeChargeVld, variation-point={short-label=vpOUT_SendCANR_StopReqBeforeChargeVld_SendCANR_StopReqBeforeChargeVld, sw-syscond=1}
            OUT_SendCANR_TotalBatteryCapacity_SendCANR_TotalBatteryCapacity: accessed-variable=SendCANR_TotalBatteryCapacity.SendCANR_TotalBatteryCapacity, variation-point={short-label=vpOUT_SendCANR_TotalBatteryCapacity_SendCANR_TotalBatteryCapacity, sw-syscond=1}
            OUT_SendCANR_TotalBatteryCapacityVld_SendCANR_TotalBatteryCapacityVld: accessed-variable=SendCANR_TotalBatteryCapacityVld.SendCANR_TotalBatteryCapacityVld, variation-point={short-label=vpOUT_SendCANR_TotalBatteryCapacityVld_SendCANR_TotalBatteryCapacityVld, sw-syscond=1}
            OUT_SendCANR_VehicleDriveSts_SendCANR_VehicleDriveSts: accessed-variable=SendCANR_VehicleDriveSts.SendCANR_VehicleDriveSts, variation-point={short-label=vpOUT_SendCANR_VehicleDriveSts_SendCANR_VehicleDriveSts, sw-syscond=1}
            OUT_SendCANR_VehicleDriveStsVld_SendCANR_VehicleDriveStsVld: accessed-variable=SendCANR_VehicleDriveStsVld.SendCANR_VehicleDriveStsVld, variation-point={short-label=vpOUT_SendCANR_VehicleDriveStsVld_SendCANR_VehicleDriveStsVld, sw-syscond=1}
            OUT_SendCANR_DischrgngSysStatusFD11_SendCANR_DischrgngSysStatusFD11: accessed-variable=SendCANR_DischrgngSysStatusFD11.SendCANR_DischrgngSysStatusFD11
            OUT_SendCANR_DischrgngSysStatusFD11Vld_SendCANR_DischrgngSysStatusFD11Vld: accessed-variable=SendCANR_DischrgngSysStatusFD11Vld.SendCANR_DischrgngSysStatusFD11Vld
            OUT_SendCANR_Max_AllwdACOutputCurL1_SendCANR_Max_AllwdACOutputCurL1: accessed-variable=SendCANR_Max_AllwdACOutputCurL1.SendCANR_Max_AllwdACOutputCurL1, variation-point={short-label=vpOUT_SendCANR_Max_AllwdACOutputCurL1_SendCANR_Max_AllwdACOutputCurL1, sw-syscond=1}
            OUT_SendCANR_Max_AllwdACOutputCurL1Vld_SendCANR_Max_AllwdACOutputCurL1Vld: accessed-variable=SendCANR_Max_AllwdACOutputCurL1Vld.SendCANR_Max_AllwdACOutputCurL1Vld, variation-point={short-label=vpOUT_SendCANR_Max_AllwdACOutputCurL1Vld_SendCANR_Max_AllwdACOutputCurL1Vld, sw-syscond=1}
            OUT_SendCANR_Max_AllwdACOutputVltL1_SendCANR_Max_AllwdACOutputVltL1: accessed-variable=SendCANR_Max_AllwdACOutputVltL1.SendCANR_Max_AllwdACOutputVltL1, variation-point={short-label=vpOUT_SendCANR_Max_AllwdACOutputVltL1_SendCANR_Max_AllwdACOutputVltL1, sw-syscond=1}
            OUT_SendCANR_Max_AllwdACOutputVltL1Vld_SendCANR_Max_AllwdACOutputVltL1Vld: accessed-variable=SendCANR_Max_AllwdACOutputVltL1Vld.SendCANR_Max_AllwdACOutputVltL1Vld, variation-point={short-label=vpOUT_SendCANR_Max_AllwdACOutputVltL1Vld_SendCANR_Max_AllwdACOutputVltL1Vld, sw-syscond=1}
            OUT_SendCANR_HybridDriveModeSts_SendCANR_HybridDriveModeSts: accessed-variable=SendCANR_HybridDriveModeSts.SendCANR_HybridDriveModeSts
            OUT_SendCANR_HybridDriveModeStsVld_SendCANR_HybridDriveModeStsVld: accessed-variable=SendCANR_HybridDriveModeStsVld.SendCANR_HybridDriveModeStsVld
            OUT_SendCANR_PerWakeUp_Diag_FD11_SendCANR_PerWakeUp_Diag_FD11: accessed-variable=SendCANR_PerWakeUp_Diag_FD11.SendCANR_PerWakeUp_Diag_FD11
            OUT_SendCANR_PerWakeUp_Diag_FD11Vld_SendCANR_PerWakeUp_Diag_FD11Vld: accessed-variable=SendCANR_PerWakeUp_Diag_FD11Vld.SendCANR_PerWakeUp_Diag_FD11Vld
            OUT_SendCANR_PrplsnSysActive_10B_SendCANR_PrplsnSysActive_10B: accessed-variable=SendCANR_PrplsnSysActive_10B.SendCANR_PrplsnSysActive_10B
            OUT_SendCANR_PrplsnSysActive_10B_Vld_SendCANR_PrplsnSysActive_10B_Vld: accessed-variable=SendCANR_PrplsnSysActive_10B_Vld.SendCANR_PrplsnSysActive_10B_Vld
            OUT_SendCANR_WU_Timer_Value_FD11_SendCANR_WU_Timer_Value_FD11: accessed-variable=SendCANR_WU_Timer_Value_FD11.SendCANR_WU_Timer_Value_FD11
            OUT_SendCANR_WU_Timer_Value_FD11Vld_SendCANR_WU_Timer_Value_FD11Vld: accessed-variable=SendCANR_WU_Timer_Value_FD11Vld.SendCANR_WU_Timer_Value_FD11Vld
            OUT_SendCANR_IMPACTCommand_FD11_SendCANR_IMPACTCommand_FD11: accessed-variable=SendCANR_IMPACTCommand_FD11.SendCANR_IMPACTCommand_FD11
            OUT_SendCANR_IMPACTCommand_FD11Vld_SendCANR_IMPACTCommand_FD11Vld: accessed-variable=SendCANR_IMPACTCommand_FD11Vld.SendCANR_IMPACTCommand_FD11Vld
            OUT_SendCANR_IMPACTConfirm_FD11_SendCANR_IMPACTConfirm_FD11: accessed-variable=SendCANR_IMPACTConfirm_FD11.SendCANR_IMPACTConfirm_FD11
            OUT_SendCANR_IMPACTConfirm_FD11Vld_SendCANR_IMPACTConfirm_FD11Vld: accessed-variable=SendCANR_IMPACTConfirm_FD11Vld.SendCANR_IMPACTConfirm_FD11Vld
            OUT_SendCANR_MCPA_Temp_FD11_SendCANR_MCPA_Temp_FD11: accessed-variable=SendCANR_MCPA_Temp_FD11.SendCANR_MCPA_Temp_FD11, variation-point={short-label=vpOUT_SendCANR_MCPA_Temp_FD11_SendCANR_MCPA_Temp_FD11, sw-syscond=1}
            OUT_SendCANR_MCPA_Temp_FD11Vld_SendCANR_MCPA_Temp_FD11Vld: accessed-variable=SendCANR_MCPA_Temp_FD11Vld.SendCANR_MCPA_Temp_FD11Vld, variation-point={short-label=vpOUT_SendCANR_MCPA_Temp_FD11Vld_SendCANR_MCPA_Temp_FD11Vld, sw-syscond=1}
            OUT_SendCANR_MCPA_DC_Current_P_FD11_SendCANR_MCPA_DC_Current_P_FD11: accessed-variable=SendCANR_MCPA_DC_Current_P_FD11.SendCANR_MCPA_DC_Current_P_FD11, variation-point={short-label=vpOUT_SendCANR_MCPA_DC_Current_P_FD11_SendCANR_MCPA_DC_Current_P_FD11, sw-syscond=1}
            OUT_SendCANR_MCPB_Temp_FD11_SendCANR_MCPB_Temp_FD11: accessed-variable=SendCANR_MCPB_Temp_FD11.SendCANR_MCPB_Temp_FD11
            OUT_SendCANR_MCPB_Temp_FD11Vld_SendCANR_MCPB_Temp_FD11Vld: accessed-variable=SendCANR_MCPB_Temp_FD11Vld.SendCANR_MCPB_Temp_FD11Vld
            OUT_SendCANR_MCPB_DC_Current_P_FD11_SendCANR_MCPB_DC_Current_P_FD11: accessed-variable=SendCANR_MCPB_DC_Current_P_FD11.SendCANR_MCPB_DC_Current_P_FD11
            OUT_SendCANR_MCPB_DC_Current_P_FD11Vld_SendCANR_MCPB_DC_Current_P_FD11Vld: accessed-variable=SendCANR_MCPB_DC_Current_P_FD11Vld.SendCANR_MCPB_DC_Current_P_FD11Vld
            OUT_SendCANR_DriveReady_PT_FD11_SendCANR_DriveReady_PT_FD11: accessed-variable=SendCANR_DriveReady_PT_FD11.SendCANR_DriveReady_PT_FD11
            OUT_SendCANR_DriveReady_PT_FD11Vld_SendCANR_DriveReady_PT_FD11Vld: accessed-variable=SendCANR_DriveReady_PT_FD11Vld.SendCANR_DriveReady_PT_FD11Vld
            OUT_SendCANR_GearEngdForDispPTFD11_SendCANR_GearEngdForDispPTFD11: accessed-variable=SendCANR_GearEngdForDispPTFD11.SendCANR_GearEngdForDispPTFD11
            OUT_SendCANR_GearEngdForDispPTFD11Vld_SendCANR_GearEngdForDispPTFD11Vld: accessed-variable=SendCANR_GearEngdForDispPTFD11Vld.SendCANR_GearEngdForDispPTFD11Vld
            OUT_SendCANR_GearEngaged_PT_FD11_SendCANR_GearEngaged_PT_FD11: accessed-variable=SendCANR_GearEngaged_PT_FD11.SendCANR_GearEngaged_PT_FD11
            OUT_SendCANR_GearEngaged_PT_FD11Vld_SendCANR_GearEngaged_PT_FD11Vld: accessed-variable=SendCANR_GearEngaged_PT_FD11Vld.SendCANR_GearEngaged_PT_FD11Vld
            OUT_SendCANR_PtrainPrplsnActvPTFD11_SendCANR_PtrainPrplsnActvPTFD11: accessed-variable=SendCANR_PtrainPrplsnActvPTFD11.SendCANR_PtrainPrplsnActvPTFD11
            OUT_SendCANR_PtrainPrplsnActvPTFD11Vld_SendCANR_PtrainPrplsnActvPTFD11Vld: accessed-variable=SendCANR_PtrainPrplsnActvPTFD11Vld.SendCANR_PtrainPrplsnActvPTFD11Vld
            OUT_SendCANR_GearEngagedForDisplay_SendCANR_GearEngagedForDisplay: accessed-variable=SendCANR_GearEngagedForDisplay.SendCANR_GearEngagedForDisplay
            OUT_SendCANR_GearEngagedForDisplayVld_SendCANR_GearEngagedForDisplayVld: accessed-variable=SendCANR_GearEngagedForDisplayVld.SendCANR_GearEngagedForDisplayVld
            OUT_SendCANR_HVCMS_ChrgnCmpl_FD11_SendCANR_HVCMS_ChrgnCmpl_FD11: accessed-variable=SendCANR_HVCMS_ChrgnCmpl_FD11.SendCANR_HVCMS_ChrgnCmpl_FD11
            OUT_SendCANR_HVCMS_ChrgnCmpl_FD11Vld_SendCANR_HVCMS_ChrgnCmpl_FD11Vld: accessed-variable=SendCANR_HVCMS_ChrgnCmpl_FD11Vld.SendCANR_HVCMS_ChrgnCmpl_FD11Vld
            OUT_SendCANR_HVCMS_EVEgyCap_FD11_SendCANR_HVCMS_EVEgyCap_FD11: accessed-variable=SendCANR_HVCMS_EVEgyCap_FD11.SendCANR_HVCMS_EVEgyCap_FD11
            OUT_SendCANR_HVCMS_EVEgyCap_FD11Vld_SendCANR_HVCMS_EVEgyCap_FD11Vld: accessed-variable=SendCANR_HVCMS_EVEgyCap_FD11Vld.SendCANR_HVCMS_EVEgyCap_FD11Vld
            OUT_SendCANR_HVCMS_EVEgyReq_FD11_SendCANR_HVCMS_EVEgyReq_FD11: accessed-variable=SendCANR_HVCMS_EVEgyReq_FD11.SendCANR_HVCMS_EVEgyReq_FD11
            OUT_SendCANR_HVCMS_EVEgyReq_FD11Vld_SendCANR_HVCMS_EVEgyReq_FD11Vld: accessed-variable=SendCANR_HVCMS_EVEgyReq_FD11Vld.SendCANR_HVCMS_EVEgyReq_FD11Vld
            OUT_SendCANR_HVCMS_EVErrorCode_FD11_SendCANR_HVCMS_EVErrorCode_FD11: accessed-variable=SendCANR_HVCMS_EVErrorCode_FD11.SendCANR_HVCMS_EVErrorCode_FD11
            OUT_SendCANR_HVCMS_EVErrorCode_FD11Vld_SendCANR_HVCMS_EVErrorCode_FD11Vld: accessed-variable=SendCANR_HVCMS_EVErrorCode_FD11Vld.SendCANR_HVCMS_EVErrorCode_FD11Vld
            OUT_SendCANR_HVCMS_EVMaxILimit_FD11_SendCANR_HVCMS_EVMaxILimit_FD11: accessed-variable=SendCANR_HVCMS_EVMaxILimit_FD11.SendCANR_HVCMS_EVMaxILimit_FD11
            OUT_SendCANR_HVCMS_EVMaxILimit_FD11Vld_SendCANR_HVCMS_EVMaxILimit_FD11Vld: accessed-variable=SendCANR_HVCMS_EVMaxILimit_FD11Vld.SendCANR_HVCMS_EVMaxILimit_FD11Vld
            OUT_SendCANR_HVCMS_EVMaxPLimit_FD11_SendCANR_HVCMS_EVMaxPLimit_FD11: accessed-variable=SendCANR_HVCMS_EVMaxPLimit_FD11.SendCANR_HVCMS_EVMaxPLimit_FD11
            OUT_SendCANR_HVCMS_EVMaxPLimit_FD11Vld_SendCANR_HVCMS_EVMaxPLimit_FD11Vld: accessed-variable=SendCANR_HVCMS_EVMaxPLimit_FD11Vld.SendCANR_HVCMS_EVMaxPLimit_FD11Vld
            OUT_SendCANR_HVCMSEVMaxVLimit_FD11_SendCANR_HVCMSEVMaxVLimit_FD11: accessed-variable=SendCANR_HVCMSEVMaxVLimit_FD11.SendCANR_HVCMSEVMaxVLimit_FD11
            OUT_SendCANR_HVCMSEVMaxVLimit_FD11Vld_SendCANR_HVCMSEVMaxVLimit_FD11Vld: accessed-variable=SendCANR_HVCMSEVMaxVLimit_FD11Vld.SendCANR_HVCMSEVMaxVLimit_FD11Vld
            OUT_SendCANR_HVCMS_EVRESS_SOC_FD11_SendCANR_HVCMS_EVRESS_SOC_FD11: accessed-variable=SendCANR_HVCMS_EVRESS_SOC_FD11.SendCANR_HVCMS_EVRESS_SOC_FD11
            OUT_SendCANR_HVCMS_EVRESS_SOC_FD11Vld_SendCANR_HVCMS_EVRESS_SOC_FD11Vld: accessed-variable=SendCANR_HVCMS_EVRESS_SOC_FD11Vld.SendCANR_HVCMS_EVRESS_SOC_FD11Vld
            OUT_SendCANR_HVCMS_EVReady_FD11_SendCANR_HVCMS_EVReady_FD11: accessed-variable=SendCANR_HVCMS_EVReady_FD11.SendCANR_HVCMS_EVReady_FD11
            OUT_SendCANR_HVCMS_EVReady_FD11Vld_SendCANR_HVCMS_EVReady_FD11Vld: accessed-variable=SendCANR_HVCMS_EVReady_FD11Vld.SendCANR_HVCMS_EVReady_FD11Vld
            OUT_SendCANR_HVCMS_EVTarCurr_FD11_SendCANR_HVCMS_EVTarCurr_FD11: accessed-variable=SendCANR_HVCMS_EVTarCurr_FD11.SendCANR_HVCMS_EVTarCurr_FD11
            OUT_SendCANR_HVCMS_EVTarCurr_FD11Vld_SendCANR_HVCMS_EVTarCurr_FD11Vld: accessed-variable=SendCANR_HVCMS_EVTarCurr_FD11Vld.SendCANR_HVCMS_EVTarCurr_FD11Vld
            OUT_SendCANR_HVCMS_EVTarVolt_FD11_SendCANR_HVCMS_EVTarVolt_FD11: accessed-variable=SendCANR_HVCMS_EVTarVolt_FD11.SendCANR_HVCMS_EVTarVolt_FD11
            OUT_SendCANR_HVCMS_EVTarVolt_FD11Vld_SendCANR_HVCMS_EVTarVolt_FD11Vld: accessed-variable=SendCANR_HVCMS_EVTarVolt_FD11Vld.SendCANR_HVCMS_EVTarVolt_FD11Vld
            OUT_SendCANR_HVCMS_RdyToChrgSt_FD11_SendCANR_HVCMS_RdyToChrgSt_FD11: accessed-variable=SendCANR_HVCMS_RdyToChrgSt_FD11.SendCANR_HVCMS_RdyToChrgSt_FD11
            OUT_SendCANR_HVCMS_RdyToChrgSt_FD11Vld_SendCANR_HVCMS_RdyToChrgSt_FD11Vld: accessed-variable=SendCANR_HVCMS_RdyToChrgSt_FD11Vld.SendCANR_HVCMS_RdyToChrgSt_FD11Vld
            OUT_SendCANR_HVCMS_RmnTiToBuSOCFD11_SendCANR_HVCMS_RmnTiToBuSOCFD11: accessed-variable=SendCANR_HVCMS_RmnTiToBuSOCFD11.SendCANR_HVCMS_RmnTiToBuSOCFD11
            OUT_SendCANR_HVCMS_RmnTiToBuSOCFD11Vld_SendCANR_HVCMS_RmnTiToBuSOCFD11Vld: accessed-variable=SendCANR_HVCMS_RmnTiToBuSOCFD11Vld.SendCANR_HVCMS_RmnTiToBuSOCFD11Vld
            OUT_SendCANR_HVCMS_RmnTiToFuSOCFD11_SendCANR_HVCMS_RmnTiToFuSOCFD11: accessed-variable=SendCANR_HVCMS_RmnTiToFuSOCFD11.SendCANR_HVCMS_RmnTiToFuSOCFD11
            OUT_SendCANR_HVCMS_RmnTiToFuSOCFD11Vld_SendCANR_HVCMS_RmnTiToFuSOCFD11Vld: accessed-variable=SendCANR_HVCMS_RmnTiToFuSOCFD11Vld.SendCANR_HVCMS_RmnTiToFuSOCFD11Vld
            OUT_SendCANR_HVCMS_SelEgyTrfTypFD11_SendCANR_HVCMS_SelEgyTrfTypFD11: accessed-variable=SendCANR_HVCMS_SelEgyTrfTypFD11.SendCANR_HVCMS_SelEgyTrfTypFD11
            OUT_SendCANR_HVCMS_SelEgyTrfTypFD11Vld_SendCANR_HVCMS_SelEgyTrfTypFD11Vld: accessed-variable=SendCANR_HVCMS_SelEgyTrfTypFD11Vld.SendCANR_HVCMS_SelEgyTrfTypFD11Vld
            OUT_SendCANR_HVCMS_SelPmtOptn_FD11_SendCANR_HVCMS_SelPmtOptn_FD11: accessed-variable=SendCANR_HVCMS_SelPmtOptn_FD11.SendCANR_HVCMS_SelPmtOptn_FD11
            OUT_SendCANR_HVCMS_SelPmtOptn_FD11Vld_SendCANR_HVCMS_SelPmtOptn_FD11Vld: accessed-variable=SendCANR_HVCMS_SelPmtOptn_FD11Vld.SendCANR_HVCMS_SelPmtOptn_FD11Vld
            OUT_SendCANR_HVCMS_SelServId_FD11_SendCANR_HVCMS_SelServId_FD11: accessed-variable=SendCANR_HVCMS_SelServId_FD11.SendCANR_HVCMS_SelServId_FD11
            OUT_SendCANR_HVCMS_SelServId_FD11Vld_SendCANR_HVCMS_SelServId_FD11Vld: accessed-variable=SendCANR_HVCMS_SelServId_FD11Vld.SendCANR_HVCMS_SelServId_FD11Vld
            OUT_SendCANR_HVCMS_ServCtgy_FD11_SendCANR_HVCMS_ServCtgy_FD11: accessed-variable=SendCANR_HVCMS_ServCtgy_FD11.SendCANR_HVCMS_ServCtgy_FD11
            OUT_SendCANR_HVCMS_ServCtgy_FD11Vld_SendCANR_HVCMS_ServCtgy_FD11Vld: accessed-variable=SendCANR_HVCMS_ServCtgy_FD11Vld.SendCANR_HVCMS_ServCtgy_FD11Vld
            OUT_SendCANR_HVCMS_ServScope_FD11_SendCANR_HVCMS_ServScope_FD11: accessed-variable=SendCANR_HVCMS_ServScope_FD11.SendCANR_HVCMS_ServScope_FD11, variation-point={short-label=vpOUT_SendCANR_HVCMS_ServScope_FD11_SendCANR_HVCMS_ServScope_FD11, sw-syscond=1}
            OUT_SendCANR_HVCMS_ServScope_FD11Vld_SendCANR_HVCMS_ServScope_FD11Vld: accessed-variable=SendCANR_HVCMS_ServScope_FD11Vld.SendCANR_HVCMS_ServScope_FD11Vld, variation-point={short-label=vpOUT_SendCANR_HVCMS_ServScope_FD11Vld_SendCANR_HVCMS_ServScope_FD11Vld, sw-syscond=1}
            OUT_SendCANR_V2X_HVCMSSltdEngTrfTyp_SendCANR_V2X_HVCMSSltdEngTrfTyp: accessed-variable=SendCANR_V2X_HVCMSSltdEngTrfTyp.SendCANR_V2X_HVCMSSltdEngTrfTyp, variation-point={short-label=vpOUT_SendCANR_V2X_HVCMSSltdEngTrfTyp_SendCANR_V2X_HVCMSSltdEngTrfTyp, sw-syscond=1}
            OUT_SendCANR_V2X_HVCMSSltdEngTrfTypVld_SendCANR_V2X_HVCMSSltdEngTrfTypVld: accessed-variable=SendCANR_V2X_HVCMSSltdEngTrfTypVld.SendCANR_V2X_HVCMSSltdEngTrfTypVld, variation-point={short-label=vpOUT_SendCANR_V2X_HVCMSSltdEngTrfTypVld_SendCANR_V2X_HVCMSSltdEngTrfTypVld, sw-syscond=1}
            OUT_SendCANR_VDCM_BattBulkSOC_FD11_SendCANR_VDCM_BattBulkSOC_FD11: accessed-variable=SendCANR_VDCM_BattBulkSOC_FD11.SendCANR_VDCM_BattBulkSOC_FD11, variation-point={short-label=vpOUT_SendCANR_VDCM_BattBulkSOC_FD11_SendCANR_VDCM_BattBulkSOC_FD11, sw-syscond=1}
            OUT_SendCANR_VDCM_BattBulkSOC_FD11Vld_SendCANR_VDCM_BattBulkSOC_FD11Vld: accessed-variable=SendCANR_VDCM_BattBulkSOC_FD11Vld.SendCANR_VDCM_BattBulkSOC_FD11Vld, variation-point={short-label=vpOUT_SendCANR_VDCM_BattBulkSOC_FD11Vld_SendCANR_VDCM_BattBulkSOC_FD11Vld, sw-syscond=1}
      19 x variation point proxy, all with category=CONDITION:
        VrntCT2B_BattVoltDeviationErr_CHDRbBattVoltDvatonErr: condition-access=1
        VrntCT2B_CHAdeMOProtocol_CHDReCHAdeMOProtocol: condition-access=1
        VrntCT2B_ChargedCurrentMin_CHDRIChargedCrntMin: condition-access=1
        VrntCT2B_ChargedReferenceConstant_CHDRPctChrgdRefrncCnstnt: condition-access=1
        VrntCT2B_DisplaySOC_HMIRPctHVBatSOCHCP: condition-access=1
        VrntCT2B_EVCUCP3Cmd_CHDRbEVCUCP3Cmd: condition-access=1
        VrntCT2B_EVContactorSts_CHDRbEVContactorSts: condition-access=1
        VrntCT2B_HVCMSServiceScope_OBCRdServiceScope: condition-access=1
        VrntCT2B_MCPADCCurrentP_INVRIMtrADCCrnt: condition-access=1
        VrntCT2B_MCPADCCurrentP_INVRIMtrCDCCrnt: condition-access=0
        VrntCT2B_MCPATemp_INVRTMtrATemp: condition-access=1
        VrntCT2B_MCPATemp_INVRTMtrCTemp: condition-access=0
        VrntCT2B_MaxAllwdACOutputCurrentL1_VDVRIMaxAlwdACOutCurr: condition-access=1
        VrntCT2B_MaxAllwdACOutputVoltageL1_VDVRUMaxAlwdACOutVolt: condition-access=1
        VrntCT2B_StopReqBeforeCharge_CHDRbStopReqBeforeChrg: condition-access=1
        VrntCT2B_TotalBatteryCapacity_BPCRqFullAmpHrCap: condition-access=1
        VrntCT2B_V2XHVCMSSlctdEnergyTransfType_VTHRbV2HSelEnergyTransTy: condition-access=1
        VrntCT2B_VDCMBattBulkSOC_IDCRPctBattBulkSOC: condition-access=1
        VrntCT2B_VehicleDriveSts_CHDRbVehicleDriveSts: condition-access=1
